VERSION ""

NS_ :

BS_:

BU_: PPowerSource
VAL_TABLE_ MeasurementsTable 5 "Description for the value '0x5'" 4 "Description for the value '0x4'" 3 "Description for the value '0x3'" 2 "Description for the value '0x2'" 1 "Description for the value '0x1'" 0 "Description for the value '0x0'" ;

BO_ 3221225472 VECTOR__INDEPENDENT_SIG_MSG: 0 Vector__XXX
 SG_ Get_Prot_RMS_Current_Level : 0|32@1- (1,0) [0|10] "" Vector__XXX
 SG_ Get_A_Apparent_Power : 0|32@1- (1,0) [-3.4E+038|3.4E+038] "" Vector__XXX
 SG_ Get_A_Current_AC : 0|32@1- (1,0) [-3.4E+038|3.4E+038] "A" Vector__XXX
 SG_ Get_VoltageLL_ACDC : 0|32@1- (1,0) [-3.4E+038|3.4E+038] "V" Vector__XXX
 SG_ Get_VoltageLL_AC : 0|32@1- (1,0) [-3.4E+038|3.4E+038] "V" Vector__XXX
 SG_ Get_VoltageLL_DC : 0|32@1- (1,0) [-3.4E+038|3.4E+038] "V" Vector__XXX
 SG_ Get_Voltage_ACDC : 0|32@1- (1,0) [-3.4E+038|3.4E+038] "V" Vector__XXX
 SG_ Get_Current_ACDC : 0|32@1- (1,0) [-3.4E+038|3.4E+038] "A" Vector__XXX
 SG_ Get_Current_AC : 0|32@1- (1,0) [-3.4E+038|3.4E+038] "A" Vector__XXX
 SG_ Get_Current_DC : 0|32@1- (1,0) [-3.4E+038|3.4E+038] "A" Vector__XXX
 SG_ Get_Peak_Current : 0|32@1- (1,0) [-3.4E+038|3.4E+038] "A" Vector__XXX
 SG_ Get_Peak_Current_Recorded : 0|32@1- (1,0) [-3.4E+038|3.4E+038] "" Vector__XXX
 SG_ Get_Active_Power : 0|32@1- (1,0) [-3.4E+038|3.4E+038] "" Vector__XXX
 SG_ Get_Apparent_Power : 0|32@1- (1,0) [-3.4E+038|3.4E+038] "" Vector__XXX
 SG_ Get_Power_Factor : 0|32@1- (1,0) [-3.4E+038|3.4E+038] "" Vector__XXX
 SG_ Get_Crest_Factor : 0|32@1- (1,0) [-3.4E+038|3.4E+038] "" Vector__XXX
 SG_ Get_Voltage_THD : 0|32@1- (1,0) [-3.4E+038|3.4E+038] "" Vector__XXX
 SG_ Get_Current_THD : 0|32@1- (1,0) [-3.4E+038|3.4E+038] "" Vector__XXX
 SG_ Get_Power_Factor_Angle : 0|32@1- (1,0) [-3.4E+038|3.4E+038] "" Vector__XXX
 SG_ Get_Displacement_Factor : 0|32@1- (1,0) [-3.4E+038|3.4E+038] "" Vector__XXX
 SG_ Get_Distortion_Factor : 0|32@1- (1,0) [-3.4E+038|3.4E+038] "" Vector__XXX
 SG_ Get_Kilowatt_Hour : 0|32@1- (1,0) [-3.4E+038|3.4E+038] "kWh" Vector__XXX
 SG_ Get_KWH_Elapsed_Time : 0|32@1- (1,0) [-3.4E+038|3.4E+038] "" Vector__XXX
 SG_ Get_C_VoltageLL_ACDC : 0|32@1- (1,0) [-3.4E+038|3.4E+038] "V" Vector__XXX
 SG_ Get_C_VoltageLL_AC : 0|32@1- (1,0) [-3.4E+038|3.4E+038] "V" Vector__XXX
 SG_ Get_C_VoltageLL_DC : 0|32@1- (1,0) [-3.4E+038|3.4E+038] "V" Vector__XXX
 SG_ Get_C_Voltage_ACDC : 0|32@1- (1,0) [-3.4E+038|3.4E+038] "V" Vector__XXX
 SG_ Get_C_Voltage_DC : 0|32@1- (1,0) [-3.4E+038|3.4E+038] "V" Vector__XXX
 SG_ Get_C_Peak_Current_Recorded : 0|32@1- (1,0) [-3.4E+038|3.4E+038] "" Vector__XXX
 SG_ Get_C_Active_Power : 0|32@1- (1,0) [-3.4E+038|3.4E+038] "" Vector__XXX
 SG_ Get_C_Apparent_Power : 0|32@1- (1,0) [-3.4E+038|3.4E+038] "" Vector__XXX
 SG_ Get_C_Crest_Factor : 0|32@1- (1,0) [-3.4E+038|3.4E+038] "" Vector__XXX
 SG_ Get_C_Voltage_THD : 0|32@1- (1,0) [-3.4E+038|3.4E+038] "" Vector__XXX
 SG_ Get_C_Power_Factor_Angle : 0|32@1- (1,0) [-3.4E+038|3.4E+038] "" Vector__XXX
 SG_ Get_C_Distortion_Factor : 0|32@1- (1,0) [-3.4E+038|3.4E+038] "" Vector__XXX
 SG_ Get_C_Kilowatt_Hour : 0|32@1- (1,0) [-3.4E+038|3.4E+038] "kWh" Vector__XXX
 SG_ Get_C_KWH_Elapsed_Time : 0|32@1- (1,0) [-3.4E+038|3.4E+038] "" Vector__XXX
 SG_ Get_B_Frequency : 0|32@1- (1,0) [-3.4E+038|3.4E+038] "Hz" Vector__XXX
 SG_ Get_B_VoltageLL_ACDC : 0|32@1- (1,0) [-3.4E+038|3.4E+038] "V" Vector__XXX
 SG_ Get_B_VoltageLL_AC : 0|32@1- (1,0) [-3.4E+038|3.4E+038] "V" Vector__XXX
 SG_ Get_B_VoltageLL_DC : 0|32@1- (1,0) [-3.4E+038|3.4E+038] "V" Vector__XXX
 SG_ Get_B_Voltage_ACDC : 0|32@1- (1,0) [-3.4E+038|3.4E+038] "V" Vector__XXX
 SG_ Get_B_Voltage_DC : 0|32@1- (1,0) [-3.4E+038|3.4E+038] "V" Vector__XXX
 SG_ Get_B_Current_ACDC : 0|32@1- (1,0) [-3.4E+038|3.4E+038] "A" Vector__XXX
 SG_ Get_B_Current_AC : 0|32@1- (1,0) [-3.4E+038|3.4E+038] "A" Vector__XXX
 SG_ Get_B_Current_DC : 0|32@1- (1,0) [-3.4E+038|3.4E+038] "A" Vector__XXX
 SG_ Get_B_Peak_Current : 0|32@1- (1,0) [-3.4E+038|3.4E+038] "A" Vector__XXX
 SG_ Get_B_Peak_Current_Recorded : 0|32@1- (1,0) [-3.4E+038|3.4E+038] "" Vector__XXX
 SG_ Get_B_Active_Power : 0|32@1- (1,0) [-3.4E+038|3.4E+038] "" Vector__XXX
 SG_ Get_B_Apparent_Power : 0|32@1- (1,0) [-3.4E+038|3.4E+038] "" Vector__XXX
 SG_ Get_B_Power_Factor : 0|32@1- (1,0) [-3.4E+038|3.4E+038] "" Vector__XXX
 SG_ Get_B_Crest_Factor : 0|32@1- (1,0) [-3.4E+038|3.4E+038] "" Vector__XXX
 SG_ Get_B_Voltage_THD : 0|32@1- (1,0) [-3.4E+038|3.4E+038] "" Vector__XXX
 SG_ Get_B_Current_THD : 0|32@1- (1,0) [-3.4E+038|3.4E+038] "" Vector__XXX
 SG_ Get_B_Power_Factor_Angle : 0|32@1- (1,0) [-3.4E+038|3.4E+038] "" Vector__XXX
 SG_ Get_B_Displacement_Factor : 0|32@1- (1,0) [-3.4E+038|3.4E+038] "" Vector__XXX
 SG_ Get_B_Distortion_Factor : 0|32@1- (1,0) [-3.4E+038|3.4E+038] "" Vector__XXX
 SG_ Get_B_Kilowatt_Hour : 0|32@1- (1,0) [-3.4E+038|3.4E+038] "kWh" Vector__XXX
 SG_ Get_B_KWH_Elapsed_Time : 0|32@1- (1,0) [-3.4E+038|3.4E+038] "" Vector__XXX
 SG_ Get_A_VoltageLL_DC : 0|32@1- (1,0) [-3.4E+038|3.4E+038] "V" Vector__XXX
 SG_ Get_A_VoltageLL_ACDC : 0|32@1- (1,0) [-3.4E+038|3.4E+038] "V" Vector__XXX
 SG_ Get_A_VoltageLL_AC : 0|32@1- (1,0) [-3.4E+038|3.4E+038] "V" Vector__XXX
 SG_ Get_A_Voltage_THD : 0|32@1- (1,0) [-3.4E+038|3.4E+038] "" Vector__XXX
 SG_ Get_A_Voltage_ACDC : 0|32@1- (1,0) [-3.4E+038|3.4E+038] "V" Vector__XXX
 SG_ Get_A_Power_Factor_Angle : 0|32@1- (1,0) [-3.4E+038|3.4E+038] "" Vector__XXX
 SG_ Get_A_Power_Factor : 0|32@1- (1,0) [-3.4E+038|3.4E+038] "" Vector__XXX
 SG_ Get_A_Peak_Current_Recorded : 0|32@1- (1,0) [-3.4E+038|3.4E+038] "" Vector__XXX
 SG_ Get_A_Peak_Current : 0|32@1- (1,0) [-3.4E+038|3.4E+038] "A" Vector__XXX
 SG_ Get_A_KWH_Elapsed_Time : 0|32@1- (1,0) [-3.4E+038|3.4E+038] "" Vector__XXX
 SG_ Get_A_Kilowatt_Hour : 0|32@1- (1,0) [-3.4E+038|3.4E+038] "kWh" Vector__XXX
 SG_ Get_A_Frequency : 0|32@1- (1,0) [-3.4E+038|3.4E+038] "Hz" Vector__XXX
 SG_ Get_A_Distortion_Factor : 0|32@1- (1,0) [-3.4E+038|3.4E+038] "" Vector__XXX
 SG_ Get_A_Displacement_Factor : 0|32@1- (1,0) [-3.4E+038|3.4E+038] "" Vector__XXX
 SG_ Get_A_Current_THD : 0|32@1- (1,0) [-3.4E+038|3.4E+038] "" Vector__XXX
 SG_ Get_A_Current_DC : 0|32@1- (1,0) [-3.4E+038|3.4E+038] "A" Vector__XXX
 SG_ Get_A_Current_ACDC : 0|32@1- (1,0) [-3.4E+038|3.4E+038] "A" Vector__XXX
 SG_ Get_A_Crest_Factor : 0|32@1- (1,0) [-3.4E+038|3.4E+038] "" Vector__XXX
 SG_ Get_A_Active_Power : 0|32@1- (1,0) [-3.4E+038|3.4E+038] "" Vector__XXX
 SG_ Firmware_Version : 0|16@1+ (1,0) [0|65535] "" Vector__XXX
 SG_ Can_Version : 0|16@1+ (1,0) [0|65535] "" Vector__XXX
 SG_ SCPI_Response_Next_Page : 0|8@1+ (1,0) [0|10] "" Vector__XXX
 SG_ SCPI_Char_16_Endianess : 0|8@1+ (1,0) [0|10] "" Vector__XXX
 SG_ SCPI_COMMAND_LAST_ASWER : 0|16@1+ (1,0) [0|255] "" Vector__XXX
 SG_ SCPI_WRITE_QUERY : 0|16@1+ (1,0) [0|255] "" Vector__XXX
 SG_ Protection_Peak_Voltage_Level : 0|32@1- (1,0) [-3.4E+038|3.4E+038] "" Vector__XXX
 SG_ Protection_Peak_Voltage_Margin : 0|32@1- (1,0) [-3.4E+038|3.4E+038] "" Vector__XXX
 SG_ Protection_Peak_Current_Level : 0|32@1- (1,0) [-3.4E+038|3.4E+038] "" Vector__XXX
 SG_ Protection_Peak_Current_Limit : 0|32@1- (1,0) [-3.4E+038|3.4E+038] "" Vector__XXX
 SG_ Protection_Trip_Time : 0|32@1- (1,0) [-3.4E+038|3.4E+038] "" Vector__XXX
 SG_ Protection_RMS_Current_Level : 0|32@1- (1,0) [-3.4E+038|3.4E+038] "" Vector__XXX
 SG_ Set_Enable_KWH : 0|8@1+ (1,0) [0|10] "" Vector__XXX
 SG_ Set_Reset_KWH : 0|8@1+ (1,0) [0|10] "" Vector__XXX
 SG_ Periodic_C_KWH_Elapsed_Time : 0|32@1- (1,0) [-3.4E+038|3.4E+038] "" Vector__XXX
 SG_ Periodic_B_KWH_Elapsed_Time : 0|32@1- (1,0) [-3.4E+038|3.4E+038] "" Vector__XXX
 SG_ Periodic_A_KWH_Elapsed_Time : 0|32@1- (1,0) [-3.4E+038|3.4E+038] "" Vector__XXX
 SG_ Periodic_C_Kilowatt_Hour : 0|32@1- (1,0) [-3.4E+038|3.4E+038] "kWh" Vector__XXX
 SG_ Periodic_B_Kilowatt_Hour : 0|32@1- (1,0) [-3.4E+038|3.4E+038] "kWh" Vector__XXX
 SG_ Periodic_C_Distortion_Factor : 0|32@1- (1,0) [-3.4E+038|3.4E+038] "" Vector__XXX
 SG_ Periodic_B_Distortion_Factor : 0|32@1- (1,0) [-3.4E+038|3.4E+038] "" Vector__XXX
 SG_ Periodic_A_Distortion_Factor : 0|32@1- (1,0) [-3.4E+038|3.4E+038] "" Vector__XXX
 SG_ Periodic_C_Displacement_Factor : 0|32@1- (1,0) [-3.4E+038|3.4E+038] "" Vector__XXX
 SG_ Periodic_B_Displacement_Factor : 0|32@1- (1,0) [-3.4E+038|3.4E+038] "" Vector__XXX
 SG_ Periodic_A_Displacement_Factor : 0|32@1- (1,0) [-3.4E+038|3.4E+038] "" Vector__XXX
 SG_ Periodic_C_Power_Factor_Angle : 0|32@1- (1,0) [-3.4E+038|3.4E+038] "" Vector__XXX
 SG_ Periodic_B_Power_Factor_Angle : 0|32@1- (1,0) [-3.4E+038|3.4E+038] "" Vector__XXX
 SG_ Periodic_C_Current_THD : 0|32@1- (1,0) [-3.4E+038|3.4E+038] "" Vector__XXX
 SG_ Periodic_B_Current_THD : 0|32@1- (1,0) [-3.4E+038|3.4E+038] "" Vector__XXX
 SG_ Periodic_C_Voltage_THD : 0|32@1- (1,0) [-3.4E+038|3.4E+038] "" Vector__XXX
 SG_ Periodic_B_Voltage_THD : 0|32@1- (1,0) [-3.4E+038|3.4E+038] "" Vector__XXX
 SG_ Periodic_C_Peak_Current_Recoded : 0|32@1- (1,0) [-3.4E+038|3.4E+038] "" Vector__XXX
 SG_ Periodic_B_Peak_Current_Recoded : 0|32@1- (1,0) [-3.4E+038|3.4E+038] "" Vector__XXX
 SG_ Periodic_C_Crest_Factor : 0|32@1- (1,0) [-3.4E+038|3.4E+038] "" Vector__XXX
 SG_ Periodic_B_Crest_Factor : 0|32@1- (1,0) [-3.4E+038|3.4E+038] "" Vector__XXX
 SG_ Periodic_A_Crest_Factor : 0|32@1- (1,0) [-3.4E+038|3.4E+038] "" Vector__XXX
 SG_ Periodic_C_Power_Factor : 0|32@1- (1,0) [-3.4E+038|3.4E+038] "" Vector__XXX
 SG_ Periodic_B_Power_Factor : 0|32@1- (1,0) [-3.4E+038|3.4E+038] "" Vector__XXX
 SG_ Periodic_C_Peak_Current : 0|32@1- (1,0) [-3.4E+038|3.4E+038] "A" Vector__XXX
 SG_ Periodic_B_Peak_Current : 0|32@1- (1,0) [-3.4E+038|3.4E+038] "A" Vector__XXX
 SG_ Periodic_C_Active_Power : 0|32@1- (1,0) [-3.4E+038|3.4E+038] "" Vector__XXX
 SG_ Periodic_C_Current_DC : 0|32@1- (1,0) [-3.4E+038|3.4E+038] "A" Vector__XXX
 SG_ Periodic_B_Current_DC : 0|32@1- (1,0) [-3.4E+038|3.4E+038] "A" Vector__XXX
 SG_ Periodic_C_Current_ACDC : 0|32@1- (1,0) [-3.4E+038|3.4E+038] "A" Vector__XXX
 SG_ Periodic_B_Current_ACDC : 0|32@1- (1,0) [-3.4E+038|3.4E+038] "A" Vector__XXX
 SG_ Periodic_C_Voltage_DC : 0|32@1- (1,0) [-3.4E+038|3.4E+038] "V" Vector__XXX
 SG_ Periodic_B_Voltage_DC : 0|32@1- (1,0) [-3.4E+038|3.4E+038] "V" Vector__XXX
 SG_ Periodic_C_Voltage_AC : 0|32@1- (1,0) [-3.4E+038|3.4E+038] "V" Vector__XXX
 SG_ Periodic_B_Voltage_AC : 0|32@1- (1,0) [-3.4E+038|3.4E+038] "V" Vector__XXX
 SG_ Periodic_C_Voltage_ACDC : 0|32@1- (1,0) [-3.4E+038|3.4E+038] "V" Vector__XXX
 SG_ Periodic_B_Voltage_ACDC : 0|32@1- (1,0) [-3.4E+038|3.4E+038] "V" Vector__XXX
 SG_ Periodic_C_VoltageLL_DC : 0|32@1- (1,0) [-3.4E+038|3.4E+038] "V" Vector__XXX
 SG_ Periodic_B_VoltageLL_DC : 0|32@1- (1,0) [-3.4E+038|3.4E+038] "V" Vector__XXX
 SG_ Periodic_C_VoltageLL_AC : 0|32@1- (1,0) [-3.4E+038|3.4E+038] "V" Vector__XXX
 SG_ Periodic_B_VoltageLL_AC : 0|32@1- (1,0) [-3.4E+038|3.4E+038] "V" Vector__XXX
 SG_ Periodic_C_VoltageLL_ACDC : 0|32@1- (1,0) [-3.4E+038|3.4E+038] "V" Vector__XXX
 SG_ Periodic_B_VoltageLL_ACDC : 0|32@1- (1,0) [-3.4E+038|3.4E+038] "V" Vector__XXX
 SG_ Periodic_C_Frequency : 0|32@1- (1,0) [-3.4E+038|3.4E+038] "Hz" Vector__XXX
 SG_ Periodic_B_Frequency : 0|32@1- (1,0) [-3.4E+038|3.4E+038] "Hz" Vector__XXX
 SG_ Periodic_A_Frequency : 0|32@1- (1,0) [-3.4E+038|3.4E+038] "Hz" Vector__XXX
 SG_ Get_Set_Phase_Offset_Output_C : 0|32@1- (1,0) [-3.4E+038|3.4E+038] "" Vector__XXX
 SG_ Get_Set_Phase_Offset_Output_B : 0|32@1- (1,0) [-3.4E+038|3.4E+038] "" Vector__XXX
 SG_ Get_Set_KVA_Limit_C : 0|32@1- (1,0) [-3.4E+038|3.4E+038] "" Vector__XXX
 SG_ Get_Set_KVA_Limit_B : 0|32@1- (1,0) [-3.4E+038|3.4E+038] "" Vector__XXX
 SG_ Get_Set_KVA_Limit_A : 0|32@1- (1,0) [-3.4E+038|3.4E+038] "" Vector__XXX
 SG_ Get_Set_Current_Limit_C : 0|32@1- (1,0) [-3.4E+038|3.4E+038] "" Vector__XXX
 SG_ Get_Set_Current_Limit_B : 0|32@1- (1,0) [-3.4E+038|3.4E+038] "" Vector__XXX
 SG_ Get_Set_Power_Limit_C : 0|32@1- (1,0) [-3.4E+038|3.4E+038] "" Vector__XXX
 SG_ Get_Set_Power_Limit_B : 0|32@1- (1,0) [-3.4E+038|3.4E+038] "" Vector__XXX
 SG_ Get_Set_Power_Limit_A : 0|32@1- (1,0) [-3.4E+038|3.4E+038] "" Vector__XXX
 SG_ Get_Set_Program_Voltage_DC_C : 0|32@1- (1,0) [-3.4E+038|3.4E+038] "" Vector__XXX
 SG_ Get_Set_Program_Voltage_DC_B : 0|32@1- (1,0) [-3.4E+038|3.4E+038] "" Vector__XXX
 SG_ Get_Set_Program_Voltage_DC_A : 0|32@1- (1,0) [-3.4E+038|3.4E+038] "" Vector__XXX
 SG_ Get_Set_Program_Voltage_AC_C : 0|32@1- (1,0) [-3.4E+038|3.4E+038] "" Vector__XXX
 SG_ Get_Set_Program_Voltage_AC_B : 0|32@1- (1,0) [-3.4E+038|3.4E+038] "" Vector__XXX
 SG_ Get_Set_Program_Voltage_AC_A : 0|32@1- (1,0) [-3.4E+038|3.4E+038] "" Vector__XXX
 SG_ Get_Set_Program_Voltage_AC : 0|32@1- (1,0) [-3.4E+038|3.4E+038] "" Vector__XXX
 SG_ Get_Set_Program_Frequency_C : 0|32@1- (1,0) [-3.4E+038|3.4E+038] "" Vector__XXX
 SG_ Get_Set_Program_Frequency_B : 0|32@1- (1,0) [-3.4E+038|3.4E+038] "" Vector__XXX
 SG_ Get_Set_Program_Frequency_A : 0|32@1- (1,0) [-3.4E+038|3.4E+038] "" Vector__XXX
 SG_ Get_Prot_Peak_Voltage_Level : 0|32@1- (1,0) [-3.4E+038|3.4E+038] "" Vector__XXX
 SG_ Get_Prot_Peak_Voltage_Margin : 0|32@1- (1,0) [-3.4E+038|3.4E+038] "" Vector__XXX
 SG_ Get_Prot_Peak_Current_Level : 0|32@1- (1,0) [-3.4E+038|3.4E+038] "" Vector__XXX
 SG_ Get_Prot_Peak_Current_Limit : 0|32@1- (1,0) [-3.4E+038|3.4E+038] "" Vector__XXX
 SG_ Get_Prot_Trip_Time : 0|32@1- (1,0) [-3.4E+038|3.4E+038] "" Vector__XXX
 SG_ Protection_Power_Level : 0|32@1- (1,0) [-3.4E+038|3.4E+038] "" Vector__XXX
 SG_ Protection_KVA_Level : 0|32@1- (1,0) [-3.4E+038|3.4E+038] "" Vector__XXX
 SG_ Protection_RMS_Power : 0|8@1+ (1,0) [0|10] "" Vector__XXX
 SG_ Protection_RMS_Current : 0|8@1+ (1,0) [0|10] "" Vector__XXX
 SG_ Protection_Peak_Voltage_Mode : 0|8@1+ (1,0) [0|10] "" Vector__XXX
 SG_ Protection_Peak_Voltage : 0|8@1+ (1,0) [0|10] "" Vector__XXX
 SG_ Protection_Peak_Current : 0|8@1+ (1,0) [0|10] "" Vector__XXX
 SG_ Get_Prot_KVA_Level : 0|32@1- (1,0) [-3.4E+038|3.4E+038] "" Vector__XXX
 SG_ Get_Prot_Power_Level : 0|32@1- (1,0) [-3.4E+038|3.4E+038] "" Vector__XXX
 SG_ Get_Prot_RMS_Power : 0|8@1+ (1,0) [0|10] "" Vector__XXX
 SG_ Get_Prot_RMS_Current : 0|8@1+ (1,0) [0|10] "" Vector__XXX
 SG_ Get_Prot_Peak_Voltage_Mode : 0|8@1+ (1,0) [0|10] "" Vector__XXX
 SG_ Get_Prot_Peak_Current : 0|8@1+ (1,0) [0|10] "" Vector__XXX
 SG_ Get_Prot_Peak_Voltage : 0|8@1+ (1,0) [0|10] "" Vector__XXX
 SG_ Get_Set_Enable_Output : 0|8@1+ (1,0) [0|255] "" Vector__XXX
 SG_ Get_Set_Program_Voltage_DC : 0|32@1- (1,0) [-3.4E+038|3.4E+038] "" Vector__XXX
 SG_ Get_Set_Power_Limit : 0|32@1- (1,0) [-3.4E+038|3.4E+038] "" Vector__XXX
 SG_ Get_Set_KVA_Limit : 0|32@1- (1,0) [-3.4E+038|3.4E+038] "" Vector__XXX
 SG_ Get_Set_Current_Limit : 0|32@1- (1,0) [-3.4E+038|3.4E+038] "" Vector__XXX
 SG_ Get_Set_Current_Limit_A : 0|32@1- (1,0) [-3.4E+038|3.4E+038] "" Vector__XXX
 SG_ Multiplex_Get_Setpoints : 0|8@1+ (1,0) [0|0] "" Vector__XXX
 SG_ Get_Set_Program_Frequency : 0|32@1- (1,0) [-3.4E+038|3.4E+038] "" Vector__XXX
 SG_ Get_B_Voltage_AC : 0|32@1- (1,0) [-3.4E+038|3.4E+038] "V" Vector__XXX
 SG_ Get_Frequency : 0|32@1- (1,0) [-3.4E+038|3.4E+038] "Hz" Vector__XXX
 SG_ Multiplex_Get_Values : 0|8@1+ (1,0) [0|0] "" Vector__XXX
 SG_ Get_C_Power_Factor : 0|32@1- (1,0) [-3.4E+038|3.4E+038] "" Vector__XXX
 SG_ Get_C_Peak_Current : 0|32@1- (1,0) [-3.4E+038|3.4E+038] "A" Vector__XXX
 SG_ Get_C_Frequency : 0|32@1- (1,0) [-3.4E+038|3.4E+038] "Hz" Vector__XXX
 SG_ Get_C_Displacement_Factor : 0|32@1- (1,0) [-3.4E+038|3.4E+038] "" Vector__XXX
 SG_ Get_C_Current_THD : 0|32@1- (1,0) [-3.4E+038|3.4E+038] "" Vector__XXX
 SG_ Get_C_Current_DC : 0|32@1- (1,0) [-3.4E+038|3.4E+038] "A" Vector__XXX
 SG_ Get_C_Current_ACDC : 0|32@1- (1,0) [-3.4E+038|3.4E+038] "A" Vector__XXX
 SG_ Get_C_Current_AC : 0|32@1- (1,0) [-3.4E+038|3.4E+038] "A" Vector__XXX
 SG_ Get_C_Voltage_AC : 0|32@1- (1,0) [-3.4E+038|3.4E+038] "V" Vector__XXX
 SG_ Get_A_Voltage_DC : 0|32@1- (1,0) [-3.4E+038|3.4E+038] "V" Vector__XXX
 SG_ Get_A_Voltage_AC : 0|32@1- (1,0) [-3.4E+038|3.4E+038] "V" Vector__XXX
 SG_ Multiplex_Periodic_Values_2 : 0|8@1+ (1,0) [0|0] "" Vector__XXX
 SG_ Periodic_A_Current_THD : 0|32@1- (1,0) [-3.4E+038|3.4E+038] "" Vector__XXX
 SG_ Periodic_A_Current_DC : 0|32@1- (1,0) [-3.4E+038|3.4E+038] "A" Vector__XXX
 SG_ Periodic_A_Current_ACDC : 0|32@1- (1,0) [-3.4E+038|3.4E+038] "A" Vector__XXX
 SG_ Multiplex_Periodic_Values_1 : 0|8@1+ (1,0) [0|0] "" Vector__XXX
 SG_ Ack_App_Signal : 0|16@1+ (1,0) [0|15] "" Vector__XXX
 SG_ Setpoint_Power_Limit_C : 0|32@1- (1,0) [-3.4E+038|3.4E+038] "" Vector__XXX
 SG_ Setpoint_Power_Limit_B : 0|32@1- (1,0) [-3.4E+038|3.4E+038] "" Vector__XXX
 SG_ Setpoint_Power_Limit_A : 0|32@1- (1,0) [-3.4E+038|3.4E+038] "" Vector__XXX
 SG_ Setpoint_Power_Limit : 0|32@1- (1,0) [-3.4E+038|3.4E+038] "" Vector__XXX
 SG_ Setpoint_Phase_Offset_Output_C : 0|32@1- (1,0) [-3.4E+038|3.4E+038] "" Vector__XXX
 SG_ Setpoint_Phase_Offset_Output_B : 0|32@1- (1,0) [-3.4E+038|3.4E+038] "" Vector__XXX
 SG_ Setpoint_KVA_Limit_C : 0|32@1- (1,0) [-3.4E+038|3.4E+038] "" Vector__XXX
 SG_ Setpoint_KVA_Limit_B : 0|32@1- (1,0) [-3.4E+038|3.4E+038] "" Vector__XXX
 SG_ Setpoint_KVA_Limit_A : 0|32@1- (1,0) [-3.4E+038|3.4E+038] "" Vector__XXX
 SG_ Setpoint_KVA_Limit : 0|32@1- (1,0) [-3.4E+038|3.4E+038] "" Vector__XXX
 SG_ Setpoint_Enable_Output : 0|8@1+ (1,0) [0|10] "" Vector__XXX
 SG_ Setpoint_Current_Limit_C : 0|32@1- (1,0) [-3.4E+038|3.4E+038] "" Vector__XXX
 SG_ Setpoint_Current_Limit_B : 0|32@1- (1,0) [-3.4E+038|3.4E+038] "" Vector__XXX
 SG_ Setpoint_Current_Limit : 0|32@1- (1,0) [-3.4E+038|3.4E+038] "" Vector__XXX
 SG_ Setpoint_Current_Limit_A : 0|32@1- (1,0) [-3.4E+038|3.4E+038] "" Vector__XXX
 SG_ Setpoint_Program_Voltage_DC_C : 0|32@1- (1,0) [-3.4E+038|3.4E+038] "" Vector__XXX
 SG_ Setpoint_Program_Voltage_DC_B : 0|32@1- (1,0) [-3.4E+038|3.4E+038] "" Vector__XXX
 SG_ Setpoint_Program_Voltage_DC_A : 0|32@1- (1,0) [-3.4E+038|3.4E+038] "" Vector__XXX
 SG_ Setpoint_Program_Voltage_DC : 0|32@1- (1,0) [-3.4E+038|3.4E+038] "" Vector__XXX
 SG_ Setpoint_Program_Voltage_AC_C : 0|32@1- (1,0) [-3.4E+038|3.4E+038] "" Vector__XXX
 SG_ Setpoint_Program_Voltage_AC_B : 0|32@1- (1,0) [-3.4E+038|3.4E+038] "" Vector__XXX
 SG_ Setpoint_Program_Voltage_AC_A : 0|32@1- (1,0) [-3.4E+038|3.4E+038] "" Vector__XXX
 SG_ Setpoint_Program_Voltage_AC : 0|32@1- (1,0) [-3.4E+038|3.4E+038] "" Vector__XXX
 SG_ Setpoint_Program_Frequency_C : 0|32@1- (1,0) [-3.4E+038|3.4E+038] "" Vector__XXX
 SG_ Setpoint_Program_Frequency_B : 0|32@1- (1,0) [-3.4E+038|3.4E+038] "" Vector__XXX
 SG_ Setpoint_Program_Frequency_A : 0|32@1- (1,0) [-3.4E+038|3.4E+038] "" Vector__XXX
 SG_ Setpoint_Program_Frequency : 0|32@1- (1,0) [-3.4E+038|3.4E+038] "" Vector__XXX
 SG_ Multiplex_Setpoint_Program : 0|8@1+ (1,0) [0|255] "" Vector__XXX
 SG_ Get_Con_Slew_Voltage_DC : 0|32@1- (1,0) [-3.4E+038|3.4E+038] "" Vector__XXX
 SG_ Get_Con_Slew_Voltage_AC : 0|32@1- (1,0) [-3.4E+038|3.4E+038] "" Vector__XXX
 SG_ Get_Con_Slew_Ramp_Time : 0|32@1- (1,0) [-3.4E+038|3.4E+038] "s" Vector__XXX
 SG_ Get_Con_Slew_Phase : 0|32@1- (1,0) [-3.4E+038|3.4E+038] "" Vector__XXX
 SG_ Get_Con_Slew_Frequency : 0|32@1- (1,0) [-3.4E+038|3.4E+038] "" Vector__XXX
 SG_ Config_Slew_Voltage_DC : 0|32@1- (1,0) [-3.4E+038|3.4E+038] "" Vector__XXX
 SG_ Config_Slew_Voltage_AC : 0|32@1- (1,0) [-3.4E+038|3.4E+038] "" Vector__XXX
 SG_ Config_Slew_Ramp_Time : 0|32@1- (1,0) [-3.4E+038|3.4E+038] "s" Vector__XXX
 SG_ Config_Slew_Phase : 0|32@1- (1,0) [-3.4E+038|3.4E+038] "" Vector__XXX
 SG_ Multiplex_Config_Slew : 0|4@1+ (1,0) [0|15] "" Vector__XXX
 SG_ Config_Slew_Frequency : 0|32@1- (1,0) [-3.4E+038|3.4E+038] "" Vector__XXX
 SG_ Get_Con_Unit_Max_CSC_Gain : 0|32@1- (1,0) [-3.4E+038|3.4E+038] "" Vector__XXX
 SG_ Get_Con_Unit_Out_Phase_Disable : 0|32@1- (1,0) [-3.4E+038|3.4E+038] "" Vector__XXX
 SG_ Get_Con_Unit_Update_Phase : 0|32@1- (1,0) [-3.4E+038|3.4E+038] "" Vector__XXX
 SG_ Config_Unit_Update_Phase : 0|32@1- (1,0) [-3.4E+038|3.4E+038] "" Vector__XXX
 SG_ Config_Unit_Out_Phase_Disable : 0|32@1- (1,0) [-3.4E+038|3.4E+038] "" Vector__XXX
 SG_ Config_Unit_Max_CSC_Gain : 0|32@1- (1,0) [-3.4E+038|3.4E+038] "" Vector__XXX
 SG_ Multiplexor_Config_Unit : 0|8@1+ (1,0) [0|15] "" Vector__XXX
 SG_ Config_Unit_Voltage_Range : 0|8@1+ (1,0) [0|255] "" Vector__XXX
 SG_ Config_Unit_Phase_Rotation : 0|8@1+ (1,0) [0|255] "" Vector__XXX
 SG_ Config_Unit_Out_Impedance_Mode : 0|8@1+ (1,0) [0|255] "" Vector__XXX
 SG_ Config_Unit_Mode : 0|8@1+ (1,0) [0|255] "" Vector__XXX
 SG_ Config_Unit_Form : 0|8@1+ (1,0) [1|255] "" Vector__XXX
 SG_ Config_Unit_Fault_On_Saturation : 0|8@1+ (1,0) [0|255] "" Vector__XXX
 SG_ Config_Unit_C_Self_Calibration : 0|8@1+ (1,0) [0|255] "" Vector__XXX

BO_ 119 Recep_meas: 8 Vector__XXX
 SG_ Get_Voltage_DC : 32|32@1- (1,0) [-3.4E+038|3.4E+038] "V" Vector__XXX
 SG_ Get_Voltage_AC : 0|32@1- (1,0) [-3.4E+038|3.4E+038] "V" Vector__XXX

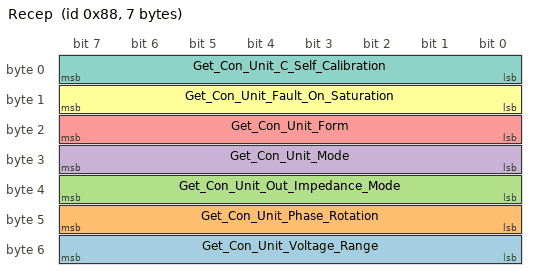
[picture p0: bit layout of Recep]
BO_ 136 Recep: 7 Vector__XXX
 SG_ Get_Con_Unit_Voltage_Range : 48|8@1+ (1,0) [0|255] "" Vector__XXX
 SG_ Get_Con_Unit_Phase_Rotation : 40|8@1+ (1,0) [0|10] "" Vector__XXX
 SG_ Get_Con_Unit_Out_Impedance_Mode : 32|8@1+ (1,0) [0|255] "" Vector__XXX
 SG_ Get_Con_Unit_Mode : 24|8@1+ (1,0) [0|255] "" Vector__XXX
 SG_ Get_Con_Unit_Form : 16|8@1+ (1,0) [1|255] "" Vector__XXX
 SG_ Get_Con_Unit_Fault_On_Saturation : 8|8@1+ (1,0) [0|255] "" Vector__XXX
 SG_ Get_Con_Unit_C_Self_Calibration : 0|8@1+ (1,0) [0|255] "" Vector__XXX

BO_ 3 Periodic_Measurements_Total: 6 Vector__XXX
 SG_ Multiplex_Periodic_Values_2 M : 0|8@1+ (1,0) [0|0] "" Vector__XXX
 SG_ Periodic_VoltageLL_DC m23 : 8|32@1- (1,0) [-3.4E+038|3.4E+038] "V" Vector__XXX
 SG_ Periodic_VoltageLL_ACDC m22 : 8|32@1- (1,0) [-3.4E+038|3.4E+038] "V" Vector__XXX
 SG_ Periodic_VoltageLL_AC m21 : 8|32@1- (1,0) [-3.4E+038|3.4E+038] "V" Vector__XXX
 SG_ Periodic_Voltage_THD m19 : 8|32@1- (1,0) [-3.4E+038|3.4E+038] "" Vector__XXX
 SG_ Periodic_Voltage_DC m18 : 8|32@1- (1,0) [-3.4E+038|3.4E+038] "V" Vector__XXX
 SG_ Periodic_Voltage_ACDC m17 : 8|32@1- (1,0) [-3.4E+038|3.4E+038] "V" Vector__XXX
 SG_ Periodic_Voltage_AC m16 : 8|32@1- (1,0) [-3.4E+038|3.4E+038] "V" Vector__XXX
 SG_ Periodic_Power_Factor_Angle m15 : 8|32@1- (1,0) [-3.4E+038|3.4E+038] "" Vector__XXX
 SG_ Periodic_Power_Factor m14 : 8|32@1- (1,0) [-3.4E+038|3.4E+038] "" Vector__XXX
 SG_ Periodic_Peak_Current_Recoded m13 : 8|32@1- (1,0) [-3.4E+038|3.4E+038] "" Vector__XXX
 SG_ Periodic_Peak_Current m12 : 8|32@1- (1,0) [-3.4E+038|3.4E+038] "A" Vector__XXX
 SG_ Periodic_KWH_Elapsed_Time m11 : 8|32@1- (1,0) [-3.4E+038|3.4E+038] "" Vector__XXX
 SG_ Periodic_Kilowatt_Hour m10 : 8|32@1- (1,0) [-3.4E+038|3.4E+038] "kWh" Vector__XXX
 SG_ Periodic_Frequency m9 : 8|32@1- (1,0) [-3.4E+038|3.4E+038] "Hz" Vector__XXX
 SG_ Periodic_Distortion_Factor m8 : 8|32@1- (1,0) [-3.4E+038|3.4E+038] "" Vector__XXX
 SG_ Periodic_Displacement_Factor m7 : 8|32@1- (1,0) [-3.4E+038|3.4E+038] "" Vector__XXX
 SG_ Periodic_Current_THD m6 : 8|32@1- (1,0) [-3.4E+038|3.4E+038] "" Vector__XXX
 SG_ Periodic_Current_DC m5 : 8|32@1- (1,0) [-3.4E+038|3.4E+038] "A" Vector__XXX
 SG_ Periodic_Current_ACDC m3 : 8|32@1- (1,0) [-3.4E+038|3.4E+038] "A" Vector__XXX
 SG_ Periodic_Crest_Factor m2 : 8|32@1- (1,0) [-3.4E+038|3.4E+038] "" Vector__XXX
 SG_ Periodic_Active_Power m1 : 8|32@1- (1,0) [-3.4E+038|3.4E+038] "" Vector__XXX

BO_ 298 Periodic_Measurements_Ander: 5 Vector__XXX
 SG_ Periodic_B_Active_Power m3 : 8|32@1- (1,0) [-3.4E+038|3.4E+038] "" Vector__XXX
 SG_ Periodic_A_Voltage_DC m45 : 8|32@1- (1,0) [-3.4E+038|3.4E+038] "V" Vector__XXX
 SG_ Periodic_A_Voltage_ACDC m47 : 8|32@1- (1,0) [-3.4E+038|3.4E+038] "V" Vector__XXX
 SG_ Periodic_A_Voltage_AC m1 : 8|32@1- (1,0) [-3.4E+038|3.4E+038] "V" Vector__XXX
 SG_ Multiplex_Periodic_Values_2 M : 0|8@1+ (1,0) [0|0] "" Vector__XXX

BO_ 2 Periodic_Measurements_Peak: 5 Vector__XXX
 SG_ Periodic_A_Peak_Current_Recoded m1 : 8|32@1- (1,0) [-3.4E+038|3.4E+038] "" Vector__XXX
 SG_ Periodic_A_Peak_Current m14 : 8|32@1- (1,0) [-3.4E+038|3.4E+038] "A" Vector__XXX
 SG_ Multiplex_Periodic_Values_2 M : 0|8@1+ (1,0) [0|0] "" Vector__XXX

BO_ 5 Periodic_Measurements_Dupla: 8 Vector__XXX
 SG_ Periodic_A_Kilowatt_Hour : 32|32@1- (1,0) [-3.4E+038|3.4E+038] "kWh" Vector__XXX
 SG_ Periodic_A_Active_Power : 0|32@1- (1,0) [-3.4E+038|3.4E+038] "" Vector__XXX

BO_ 299 Periodic_Measurements_Cut: 5 Vector__XXX
 SG_ Periodic_A_Power_Factor_Angle m9 : 8|32@1- (1,0) [-3.4E+038|3.4E+038] "" Vector__XXX
 SG_ Periodic_A_Power_Factor m3 : 8|32@1- (1,0) [-3.4E+038|3.4E+038] "" Vector__XXX
 SG_ Multiplex_Periodic_Values_2 M : 0|8@1+ (1,0) [0|0] "" Vector__XXX

BO_ 4 Periodic_Measurements_Sliced: 5 Vector__XXX
 SG_ Periodic_A_VoltageLL_DC m12 : 8|32@1- (1,0) [-3.4E+038|3.4E+038] "V" Vector__XXX
 SG_ Periodic_A_VoltageLL_ACDC m22 : 8|32@1- (1,0) [-3.4E+038|3.4E+038] "V" Vector__XXX
 SG_ Periodic_A_VoltageLL_AC m35 : 8|32@1- (1,0) [-3.4E+038|3.4E+038] "V" Vector__XXX
 SG_ Periodic_A_Voltage_THD m78 : 8|32@1- (1,0) [-3.4E+038|3.4E+038] "" Vector__XXX
 SG_ Multiplex_Periodic_Values_2 M : 0|8@1+ (1,0) [0|0] "" Vector__XXX

EV_ CAN_Config: 0 [0|16] "" 5 1 DUMMY_NODE_VECTOR3 Vector__XXX;

CM_ BO_ 3221225472 "This is a message for not used signals, created by Vector CANdb++ DBC OLE DB Provider.";
CM_ SG_ 3221225472 Firmware_Version "Firmware Version";
CM_ SG_ 3221225472 Can_Version "Interface Version";
BA_DEF_ EV_  "Nominal_Bit_Rate" INT 5000 1000000;
BA_DEF_ EV_  "Data_Bit_Rate" INT 1000000 10000000;
BA_DEF_ EV_  "Mode" ENUM  "CAN (SJA1000)","CAN","ISO CAN FD","Non-ISO CAN FD";
BA_DEF_ BU_  "ISO11783PDDVersion" ENUM  "0","1","2","3","4";
BA_DEF_ BU_  "ISO11783IOPVersion" ENUM  "0","1","2","3","4";
BA_DEF_ BO_  "SingleFrame" INT 0 1;
BA_DEF_ SG_  "DDI" INT 0 65535;
BA_DEF_ SG_  "SigType" ENUM  "Default","Range","RangeSigned","ASCII","Discrete","Control","ReferencePGN","DTC","StringDelimiter","StringLength","StringLengthControl","MessageCounter","MessageChecksum";
BA_DEF_ SG_  "GenSigILSupport" ENUM  "No","Yes";
BA_DEF_ SG_  "GenSigSendType" ENUM  "Cyclic","OnWrite","OnWriteWithRepetition","OnChange","OnChangeWithRepetition","IfActive","IfActiveWithRepetition","NoSigSendType";
BA_DEF_ SG_  "GenSigInactiveValue" INT 0 0;
BA_DEF_ SG_  "GenSigStartValue" INT 0 2147483647;
BA_DEF_ BO_  "GenMsgILSupport" ENUM  "No","Yes";
BA_DEF_ BU_  "ECU" STRING ;
BA_DEF_ BU_  "NmStationAddress" INT 0 255;
BA_DEF_ BO_  "GenMsgSendType" ENUM  "cyclic","NotUsed","NotUsed","NotUsed","NotUsed","NotUsed","NotUsed","IfActive","noMsgSendType";
BA_DEF_ BO_  "GenMsgRequestable" INT 0 1;
BA_DEF_  "DBName" STRING ;
BA_DEF_  "BusType" STRING ;
BA_DEF_  "ProtocolType" STRING ;
BA_DEF_ BO_  "VFrameFormat" ENUM  "StandardCAN","ExtendedCAN","reserved","J1939PG";
BA_DEF_DEF_  "Nominal_Bit_Rate" 1000000;
BA_DEF_DEF_  "Data_Bit_Rate" 2000000;
BA_DEF_DEF_  "Mode" "CAN (SJA1000)";
BA_DEF_DEF_  "ISO11783PDDVersion" "3";
BA_DEF_DEF_  "ISO11783IOPVersion" "3";
BA_DEF_DEF_  "SingleFrame" 1;
BA_DEF_DEF_  "DDI" 0;
BA_DEF_DEF_  "SigType" "Default";
BA_DEF_DEF_  "GenSigILSupport" "Yes";
BA_DEF_DEF_  "GenSigSendType" "NoSigSendType";
BA_DEF_DEF_  "GenSigInactiveValue" 0;
BA_DEF_DEF_  "GenSigStartValue" 0;
BA_DEF_DEF_  "GenMsgILSupport" "Yes";
BA_DEF_DEF_  "ECU" "";
BA_DEF_DEF_  "NmStationAddress" 254;
BA_DEF_DEF_  "GenMsgSendType" "noMsgSendType";
BA_DEF_DEF_  "GenMsgRequestable" 1;
BA_DEF_DEF_  "DBName" "";
BA_DEF_DEF_  "BusType" "CAN";
BA_DEF_DEF_  "ProtocolType" "ISO11783";
BA_DEF_DEF_  "VFrameFormat" "J1939PG";
BA_ "ProtocolType" "iso11783";
BA_ "DBName" "firstdatabase";
BA_ "ECU" BU_ PPowerSource "FrontPanel";
BA_ "NmStationAddress" BU_ PPowerSource 38;
BA_ "VFrameFormat" BO_ 119 0;
BA_ "VFrameFormat" BO_ 136 0;
BA_ "VFrameFormat" BO_ 3 0;
BA_ "VFrameFormat" BO_ 298 0;
BA_ "VFrameFormat" BO_ 2 0;
BA_ "VFrameFormat" BO_ 5 0;
BA_ "VFrameFormat" BO_ 299 0;
BA_ "VFrameFormat" BO_ 4 0;
BA_ "DDI" SG_ 3221225472 Get_Prot_RMS_Current_Level 8;
BA_ "DDI" SG_ 3221225472 Get_A_Apparent_Power 1;
BA_ "DDI" SG_ 3221225472 Get_A_Current_AC 1;
BA_ "DDI" SG_ 3221225472 Get_VoltageLL_ACDC 1;
BA_ "DDI" SG_ 3221225472 Get_VoltageLL_AC 1;
BA_ "DDI" SG_ 3221225472 Get_VoltageLL_DC 1;
BA_ "DDI" SG_ 3221225472 Get_Voltage_ACDC 1;
BA_ "DDI" SG_ 3221225472 Get_Current_ACDC 1;
BA_ "DDI" SG_ 3221225472 Get_Current_AC 1;
BA_ "DDI" SG_ 3221225472 Get_Current_DC 1;
BA_ "DDI" SG_ 3221225472 Get_Peak_Current 1;
BA_ "DDI" SG_ 3221225472 Get_Peak_Current_Recorded 1;
BA_ "DDI" SG_ 3221225472 Get_Active_Power 1;
BA_ "DDI" SG_ 3221225472 Get_Apparent_Power 1;
BA_ "DDI" SG_ 3221225472 Get_Power_Factor 1;
BA_ "DDI" SG_ 3221225472 Get_Crest_Factor 1;
BA_ "DDI" SG_ 3221225472 Get_Voltage_THD 1;
BA_ "DDI" SG_ 3221225472 Get_Current_THD 1;
BA_ "DDI" SG_ 3221225472 Get_Power_Factor_Angle 1;
BA_ "DDI" SG_ 3221225472 Get_Displacement_Factor 1;
BA_ "DDI" SG_ 3221225472 Get_Distortion_Factor 1;
BA_ "DDI" SG_ 3221225472 Get_Kilowatt_Hour 1;
BA_ "DDI" SG_ 3221225472 Get_KWH_Elapsed_Time 1;
BA_ "DDI" SG_ 3221225472 Get_C_VoltageLL_ACDC 1;
BA_ "DDI" SG_ 3221225472 Get_C_VoltageLL_AC 1;
BA_ "DDI" SG_ 3221225472 Get_C_VoltageLL_DC 1;
BA_ "DDI" SG_ 3221225472 Get_C_Voltage_ACDC 1;
BA_ "DDI" SG_ 3221225472 Get_C_Voltage_DC 1;
BA_ "DDI" SG_ 3221225472 Get_C_Peak_Current_Recorded 1;
BA_ "DDI" SG_ 3221225472 Get_C_Active_Power 1;
BA_ "DDI" SG_ 3221225472 Get_C_Apparent_Power 1;
BA_ "DDI" SG_ 3221225472 Get_C_Crest_Factor 1;
BA_ "DDI" SG_ 3221225472 Get_C_Voltage_THD 1;
BA_ "DDI" SG_ 3221225472 Get_C_Power_Factor_Angle 1;
BA_ "DDI" SG_ 3221225472 Get_C_Distortion_Factor 1;
BA_ "DDI" SG_ 3221225472 Get_C_Kilowatt_Hour 1;
BA_ "DDI" SG_ 3221225472 Get_C_KWH_Elapsed_Time 1;
BA_ "DDI" SG_ 3221225472 Get_B_Frequency 1;
BA_ "DDI" SG_ 3221225472 Get_B_VoltageLL_ACDC 1;
BA_ "DDI" SG_ 3221225472 Get_B_VoltageLL_AC 1;
BA_ "DDI" SG_ 3221225472 Get_B_VoltageLL_DC 1;
BA_ "DDI" SG_ 3221225472 Get_B_Voltage_ACDC 1;
BA_ "DDI" SG_ 3221225472 Get_B_Voltage_DC 1;
BA_ "DDI" SG_ 3221225472 Get_B_Current_ACDC 1;
BA_ "DDI" SG_ 3221225472 Get_B_Current_AC 1;
BA_ "DDI" SG_ 3221225472 Get_B_Current_DC 1;
BA_ "DDI" SG_ 3221225472 Get_B_Peak_Current 1;
BA_ "DDI" SG_ 3221225472 Get_B_Peak_Current_Recorded 1;
BA_ "DDI" SG_ 3221225472 Get_B_Active_Power 1;
BA_ "DDI" SG_ 3221225472 Get_B_Apparent_Power 1;
BA_ "DDI" SG_ 3221225472 Get_B_Power_Factor 1;
BA_ "DDI" SG_ 3221225472 Get_B_Crest_Factor 1;
BA_ "DDI" SG_ 3221225472 Get_B_Voltage_THD 1;
BA_ "DDI" SG_ 3221225472 Get_B_Current_THD 1;
BA_ "DDI" SG_ 3221225472 Get_B_Power_Factor_Angle 1;
BA_ "DDI" SG_ 3221225472 Get_B_Displacement_Factor 1;
BA_ "DDI" SG_ 3221225472 Get_B_Distortion_Factor 1;
BA_ "DDI" SG_ 3221225472 Get_B_Kilowatt_Hour 1;
BA_ "DDI" SG_ 3221225472 Get_B_KWH_Elapsed_Time 1;
BA_ "DDI" SG_ 3221225472 Get_A_VoltageLL_DC 1;
BA_ "DDI" SG_ 3221225472 Get_A_VoltageLL_ACDC 1;
BA_ "DDI" SG_ 3221225472 Get_A_VoltageLL_AC 1;
BA_ "DDI" SG_ 3221225472 Get_A_Voltage_THD 1;
BA_ "DDI" SG_ 3221225472 Get_A_Voltage_ACDC 1;
BA_ "DDI" SG_ 3221225472 Get_A_Power_Factor_Angle 1;
BA_ "DDI" SG_ 3221225472 Get_A_Power_Factor 1;
BA_ "DDI" SG_ 3221225472 Get_A_Peak_Current_Recorded 1;
BA_ "DDI" SG_ 3221225472 Get_A_Peak_Current 1;
BA_ "DDI" SG_ 3221225472 Get_A_KWH_Elapsed_Time 1;
BA_ "DDI" SG_ 3221225472 Get_A_Kilowatt_Hour 1;
BA_ "DDI" SG_ 3221225472 Get_A_Frequency 1;
BA_ "DDI" SG_ 3221225472 Get_A_Distortion_Factor 1;
BA_ "DDI" SG_ 3221225472 Get_A_Displacement_Factor 1;
BA_ "DDI" SG_ 3221225472 Get_A_Current_THD 1;
BA_ "DDI" SG_ 3221225472 Get_A_Current_DC 1;
BA_ "DDI" SG_ 3221225472 Get_A_Current_ACDC 1;
BA_ "DDI" SG_ 3221225472 Get_A_Crest_Factor 1;
BA_ "DDI" SG_ 3221225472 Get_A_Active_Power 1;
BA_ "GenSigStartValue" SG_ 3221225472 Firmware_Version 10;
BA_ "GenSigStartValue" SG_ 3221225472 Can_Version 10;
BA_ "DDI" SG_ 3221225472 SCPI_Response_Next_Page 15;
BA_ "DDI" SG_ 3221225472 SCPI_Char_16_Endianess 15;
BA_ "DDI" SG_ 3221225472 SCPI_COMMAND_LAST_ASWER 15;
BA_ "DDI" SG_ 3221225472 SCPI_WRITE_QUERY 15;
BA_ "DDI" SG_ 3221225472 Protection_Peak_Voltage_Level 7;
BA_ "DDI" SG_ 3221225472 Protection_Peak_Voltage_Margin 7;
BA_ "DDI" SG_ 3221225472 Protection_Peak_Current_Level 7;
BA_ "DDI" SG_ 3221225472 Protection_Peak_Current_Limit 7;
BA_ "DDI" SG_ 3221225472 Protection_Trip_Time 7;
BA_ "DDI" SG_ 3221225472 Protection_RMS_Current_Level 7;
BA_ "DDI" SG_ 3221225472 Set_Enable_KWH 2;
BA_ "DDI" SG_ 3221225472 Set_Reset_KWH 2;
BA_ "DDI" SG_ 3221225472 Periodic_C_KWH_Elapsed_Time 1;
BA_ "DDI" SG_ 3221225472 Periodic_B_KWH_Elapsed_Time 1;
BA_ "DDI" SG_ 3221225472 Periodic_A_KWH_Elapsed_Time 1;
BA_ "DDI" SG_ 3221225472 Periodic_C_Kilowatt_Hour 1;
BA_ "DDI" SG_ 3221225472 Periodic_B_Kilowatt_Hour 1;
BA_ "DDI" SG_ 3221225472 Periodic_C_Distortion_Factor 1;
BA_ "DDI" SG_ 3221225472 Periodic_B_Distortion_Factor 1;
BA_ "DDI" SG_ 3221225472 Periodic_A_Distortion_Factor 1;
BA_ "DDI" SG_ 3221225472 Periodic_C_Displacement_Factor 1;
BA_ "DDI" SG_ 3221225472 Periodic_B_Displacement_Factor 1;
BA_ "DDI" SG_ 3221225472 Periodic_A_Displacement_Factor 1;
BA_ "DDI" SG_ 3221225472 Periodic_C_Power_Factor_Angle 1;
BA_ "DDI" SG_ 3221225472 Periodic_B_Power_Factor_Angle 1;
BA_ "DDI" SG_ 3221225472 Periodic_C_Current_THD 1;
BA_ "DDI" SG_ 3221225472 Periodic_B_Current_THD 1;
BA_ "DDI" SG_ 3221225472 Periodic_C_Voltage_THD 1;
BA_ "DDI" SG_ 3221225472 Periodic_B_Voltage_THD 1;
BA_ "DDI" SG_ 3221225472 Periodic_C_Peak_Current_Recoded 1;
BA_ "DDI" SG_ 3221225472 Periodic_B_Peak_Current_Recoded 1;
BA_ "DDI" SG_ 3221225472 Periodic_C_Crest_Factor 1;
BA_ "DDI" SG_ 3221225472 Periodic_B_Crest_Factor 1;
BA_ "DDI" SG_ 3221225472 Periodic_A_Crest_Factor 1;
BA_ "DDI" SG_ 3221225472 Periodic_C_Power_Factor 1;
BA_ "DDI" SG_ 3221225472 Periodic_B_Power_Factor 1;
BA_ "DDI" SG_ 3221225472 Periodic_C_Peak_Current 1;
BA_ "DDI" SG_ 3221225472 Periodic_B_Peak_Current 1;
BA_ "DDI" SG_ 3221225472 Periodic_C_Active_Power 1;
BA_ "DDI" SG_ 3221225472 Periodic_C_Current_DC 1;
BA_ "DDI" SG_ 3221225472 Periodic_B_Current_DC 1;
BA_ "DDI" SG_ 3221225472 Periodic_C_Current_ACDC 1;
BA_ "DDI" SG_ 3221225472 Periodic_B_Current_ACDC 1;
BA_ "DDI" SG_ 3221225472 Periodic_C_Voltage_DC 1;
BA_ "DDI" SG_ 3221225472 Periodic_B_Voltage_DC 1;
BA_ "DDI" SG_ 3221225472 Periodic_C_Voltage_AC 1;
BA_ "DDI" SG_ 3221225472 Periodic_B_Voltage_AC 1;
BA_ "DDI" SG_ 3221225472 Periodic_C_Voltage_ACDC 1;
BA_ "DDI" SG_ 3221225472 Periodic_B_Voltage_ACDC 1;
BA_ "DDI" SG_ 3221225472 Periodic_C_VoltageLL_DC 1;
BA_ "DDI" SG_ 3221225472 Periodic_B_VoltageLL_DC 1;
BA_ "DDI" SG_ 3221225472 Periodic_C_VoltageLL_AC 1;
BA_ "DDI" SG_ 3221225472 Periodic_B_VoltageLL_AC 1;
BA_ "DDI" SG_ 3221225472 Periodic_C_VoltageLL_ACDC 1;
BA_ "DDI" SG_ 3221225472 Periodic_B_VoltageLL_ACDC 1;
BA_ "DDI" SG_ 3221225472 Periodic_C_Frequency 1;
BA_ "DDI" SG_ 3221225472 Periodic_B_Frequency 1;
BA_ "DDI" SG_ 3221225472 Periodic_A_Frequency 1;
BA_ "DDI" SG_ 3221225472 Get_Set_Phase_Offset_Output_C 4;
BA_ "DDI" SG_ 3221225472 Get_Set_Phase_Offset_Output_B 4;
BA_ "DDI" SG_ 3221225472 Get_Set_KVA_Limit_C 4;
BA_ "DDI" SG_ 3221225472 Get_Set_KVA_Limit_B 4;
BA_ "DDI" SG_ 3221225472 Get_Set_KVA_Limit_A 4;
BA_ "DDI" SG_ 3221225472 Get_Set_Current_Limit_C 4;
BA_ "DDI" SG_ 3221225472 Get_Set_Current_Limit_B 4;
BA_ "DDI" SG_ 3221225472 Get_Set_Power_Limit_C 4;
BA_ "DDI" SG_ 3221225472 Get_Set_Power_Limit_B 4;
BA_ "DDI" SG_ 3221225472 Get_Set_Power_Limit_A 4;
BA_ "DDI" SG_ 3221225472 Get_Set_Program_Voltage_DC_C 4;
BA_ "DDI" SG_ 3221225472 Get_Set_Program_Voltage_DC_B 4;
BA_ "DDI" SG_ 3221225472 Get_Set_Program_Voltage_DC_A 4;
BA_ "DDI" SG_ 3221225472 Get_Set_Program_Voltage_AC_C 4;
BA_ "DDI" SG_ 3221225472 Get_Set_Program_Voltage_AC_B 4;
BA_ "DDI" SG_ 3221225472 Get_Set_Program_Voltage_AC_A 4;
BA_ "DDI" SG_ 3221225472 Get_Set_Program_Voltage_AC 4;
BA_ "DDI" SG_ 3221225472 Get_Set_Program_Frequency_C 4;
BA_ "DDI" SG_ 3221225472 Get_Set_Program_Frequency_B 4;
BA_ "DDI" SG_ 3221225472 Get_Set_Program_Frequency_A 4;
BA_ "DDI" SG_ 3221225472 Get_Prot_Peak_Voltage_Level 8;
BA_ "DDI" SG_ 3221225472 Get_Prot_Peak_Voltage_Margin 8;
BA_ "DDI" SG_ 3221225472 Get_Prot_Peak_Current_Level 8;
BA_ "DDI" SG_ 3221225472 Get_Prot_Peak_Current_Limit 8;
BA_ "DDI" SG_ 3221225472 Get_Prot_Trip_Time 8;
BA_ "DDI" SG_ 3221225472 Protection_Power_Level 7;
BA_ "DDI" SG_ 3221225472 Protection_KVA_Level 7;
BA_ "DDI" SG_ 3221225472 Protection_RMS_Power 7;
BA_ "DDI" SG_ 3221225472 Protection_RMS_Current 7;
BA_ "DDI" SG_ 3221225472 Protection_Peak_Voltage_Mode 7;
BA_ "DDI" SG_ 3221225472 Protection_Peak_Voltage 7;
BA_ "DDI" SG_ 3221225472 Protection_Peak_Current 7;
BA_ "DDI" SG_ 3221225472 Get_Prot_KVA_Level 8;
BA_ "DDI" SG_ 3221225472 Get_Prot_Power_Level 8;
BA_ "DDI" SG_ 3221225472 Get_Prot_RMS_Power 8;
BA_ "DDI" SG_ 3221225472 Get_Prot_RMS_Current 8;
BA_ "DDI" SG_ 3221225472 Get_Prot_Peak_Voltage_Mode 8;
BA_ "DDI" SG_ 3221225472 Get_Prot_Peak_Current 8;
BA_ "DDI" SG_ 3221225472 Get_Prot_Peak_Voltage 8;
BA_ "DDI" SG_ 3221225472 Get_Set_Enable_Output 4;
BA_ "DDI" SG_ 3221225472 Get_Set_Program_Voltage_DC 4;
BA_ "DDI" SG_ 3221225472 Get_Set_Power_Limit 4;
BA_ "DDI" SG_ 3221225472 Get_Set_KVA_Limit 4;
BA_ "DDI" SG_ 3221225472 Get_Set_Current_Limit 4;
BA_ "DDI" SG_ 3221225472 Get_Set_Current_Limit_A 4;
BA_ "DDI" SG_ 3221225472 Get_Set_Program_Frequency 4;
BA_ "DDI" SG_ 3221225472 Get_B_Voltage_AC 1;
BA_ "DDI" SG_ 3221225472 Get_Frequency 1;
BA_ "DDI" SG_ 3221225472 Get_C_Power_Factor 1;
BA_ "DDI" SG_ 3221225472 Get_C_Peak_Current 1;
BA_ "DDI" SG_ 3221225472 Get_C_Frequency 1;
BA_ "DDI" SG_ 3221225472 Get_C_Displacement_Factor 1;
BA_ "DDI" SG_ 3221225472 Get_C_Current_THD 1;
BA_ "DDI" SG_ 3221225472 Get_C_Current_DC 1;
BA_ "DDI" SG_ 3221225472 Get_C_Current_ACDC 1;
BA_ "DDI" SG_ 3221225472 Get_C_Current_AC 1;
BA_ "DDI" SG_ 3221225472 Get_C_Voltage_AC 1;
BA_ "DDI" SG_ 3221225472 Get_A_Voltage_DC 1;
BA_ "DDI" SG_ 3221225472 Get_A_Voltage_AC 1;
BA_ "DDI" SG_ 3221225472 Periodic_A_Current_THD 1;
BA_ "DDI" SG_ 3221225472 Periodic_A_Current_DC 1;
BA_ "DDI" SG_ 3221225472 Periodic_A_Current_ACDC 1;
BA_ "DDI" SG_ 3221225472 Setpoint_Power_Limit_C 3;
BA_ "DDI" SG_ 3221225472 Setpoint_Power_Limit_B 3;
BA_ "DDI" SG_ 3221225472 Setpoint_Power_Limit_A 3;
BA_ "DDI" SG_ 3221225472 Setpoint_Power_Limit 3;
BA_ "DDI" SG_ 3221225472 Setpoint_Phase_Offset_Output_C 3;
BA_ "DDI" SG_ 3221225472 Setpoint_Phase_Offset_Output_B 3;
BA_ "DDI" SG_ 3221225472 Setpoint_KVA_Limit_C 3;
BA_ "DDI" SG_ 3221225472 Setpoint_KVA_Limit_B 3;
BA_ "DDI" SG_ 3221225472 Setpoint_KVA_Limit_A 3;
BA_ "DDI" SG_ 3221225472 Setpoint_KVA_Limit 3;
BA_ "DDI" SG_ 3221225472 Setpoint_Enable_Output 3;
BA_ "DDI" SG_ 3221225472 Setpoint_Current_Limit_C 3;
BA_ "DDI" SG_ 3221225472 Setpoint_Current_Limit_B 3;
BA_ "DDI" SG_ 3221225472 Setpoint_Current_Limit 3;
BA_ "DDI" SG_ 3221225472 Setpoint_Current_Limit_A 3;
BA_ "DDI" SG_ 3221225472 Setpoint_Program_Voltage_DC_C 3;
BA_ "DDI" SG_ 3221225472 Setpoint_Program_Voltage_DC_B 3;
BA_ "DDI" SG_ 3221225472 Setpoint_Program_Voltage_DC_A 3;
BA_ "DDI" SG_ 3221225472 Setpoint_Program_Voltage_DC 3;
BA_ "DDI" SG_ 3221225472 Setpoint_Program_Voltage_AC_C 3;
BA_ "DDI" SG_ 3221225472 Setpoint_Program_Voltage_AC_B 3;
BA_ "DDI" SG_ 3221225472 Setpoint_Program_Voltage_AC_A 3;
BA_ "DDI" SG_ 3221225472 Setpoint_Program_Voltage_AC 3;
BA_ "DDI" SG_ 3221225472 Setpoint_Program_Frequency_C 3;
BA_ "DDI" SG_ 3221225472 Setpoint_Program_Frequency_B 3;
BA_ "DDI" SG_ 3221225472 Setpoint_Program_Frequency_A 3;
BA_ "DDI" SG_ 3221225472 Setpoint_Program_Frequency 3;
BA_ "DDI" SG_ 3221225472 Get_Con_Slew_Voltage_DC 6;
BA_ "DDI" SG_ 3221225472 Get_Con_Slew_Voltage_AC 6;
BA_ "DDI" SG_ 3221225472 Get_Con_Slew_Ramp_Time 6;
BA_ "DDI" SG_ 3221225472 Get_Con_Slew_Phase 6;
BA_ "DDI" SG_ 3221225472 Get_Con_Slew_Frequency 6;
BA_ "DDI" SG_ 3221225472 Config_Slew_Voltage_DC 5;
BA_ "DDI" SG_ 3221225472 Config_Slew_Voltage_AC 5;
BA_ "DDI" SG_ 3221225472 Config_Slew_Ramp_Time 5;
BA_ "DDI" SG_ 3221225472 Config_Slew_Phase 5;
BA_ "DDI" SG_ 3221225472 Config_Slew_Frequency 5;
BA_ "DDI" SG_ 3221225472 Get_Con_Unit_Max_CSC_Gain 6;
BA_ "DDI" SG_ 3221225472 Get_Con_Unit_Out_Phase_Disable 6;
BA_ "DDI" SG_ 3221225472 Get_Con_Unit_Update_Phase 6;
BA_ "DDI" SG_ 3221225472 Config_Unit_Update_Phase 5;
BA_ "DDI" SG_ 3221225472 Config_Unit_Out_Phase_Disable 5;
BA_ "DDI" SG_ 3221225472 Config_Unit_Max_CSC_Gain 5;
BA_ "DDI" SG_ 3221225472 Config_Unit_Voltage_Range 5;
BA_ "DDI" SG_ 3221225472 Config_Unit_Phase_Rotation 5;
BA_ "DDI" SG_ 3221225472 Config_Unit_Out_Impedance_Mode 5;
BA_ "DDI" SG_ 3221225472 Config_Unit_Mode 5;
BA_ "DDI" SG_ 3221225472 Config_Unit_Form 5;
BA_ "GenSigStartValue" SG_ 3221225472 Config_Unit_Form 1;
BA_ "DDI" SG_ 3221225472 Config_Unit_Fault_On_Saturation 5;
BA_ "DDI" SG_ 3221225472 Config_Unit_C_Self_Calibration 5;
BA_ "DDI" SG_ 119 Get_Voltage_DC 1;
BA_ "DDI" SG_ 119 Get_Voltage_AC 1;
BA_ "DDI" SG_ 136 Get_Con_Unit_Voltage_Range 6;
BA_ "DDI" SG_ 136 Get_Con_Unit_Phase_Rotation 6;
BA_ "DDI" SG_ 136 Get_Con_Unit_Out_Impedance_Mode 6;
BA_ "DDI" SG_ 136 Get_Con_Unit_Mode 6;
BA_ "DDI" SG_ 136 Get_Con_Unit_Form 6;
BA_ "GenSigStartValue" SG_ 136 Get_Con_Unit_Form 1;
BA_ "DDI" SG_ 136 Get_Con_Unit_Fault_On_Saturation 6;
BA_ "DDI" SG_ 136 Get_Con_Unit_C_Self_Calibration 6;
BA_ "DDI" SG_ 3 Periodic_VoltageLL_DC 1;
BA_ "DDI" SG_ 3 Periodic_VoltageLL_ACDC 1;
BA_ "DDI" SG_ 3 Periodic_VoltageLL_AC 1;
BA_ "DDI" SG_ 3 Periodic_Voltage_THD 1;
BA_ "DDI" SG_ 3 Periodic_Voltage_DC 1;
BA_ "DDI" SG_ 3 Periodic_Voltage_ACDC 1;
BA_ "DDI" SG_ 3 Periodic_Voltage_AC 1;
BA_ "DDI" SG_ 3 Periodic_Power_Factor_Angle 1;
BA_ "DDI" SG_ 3 Periodic_Power_Factor 1;
BA_ "DDI" SG_ 3 Periodic_Peak_Current_Recoded 1;
BA_ "DDI" SG_ 3 Periodic_Peak_Current 1;
BA_ "DDI" SG_ 3 Periodic_KWH_Elapsed_Time 1;
BA_ "DDI" SG_ 3 Periodic_Kilowatt_Hour 1;
BA_ "DDI" SG_ 3 Periodic_Frequency 1;
BA_ "DDI" SG_ 3 Periodic_Distortion_Factor 1;
BA_ "DDI" SG_ 3 Periodic_Displacement_Factor 1;
BA_ "DDI" SG_ 3 Periodic_Current_THD 1;
BA_ "DDI" SG_ 3 Periodic_Current_DC 1;
BA_ "DDI" SG_ 3 Periodic_Current_ACDC 1;
BA_ "DDI" SG_ 3 Periodic_Crest_Factor 1;
BA_ "DDI" SG_ 3 Periodic_Active_Power 1;
BA_ "DDI" SG_ 298 Periodic_B_Active_Power 1;
BA_ "DDI" SG_ 298 Periodic_A_Voltage_DC 1;
BA_ "DDI" SG_ 298 Periodic_A_Voltage_ACDC 1;
BA_ "DDI" SG_ 298 Periodic_A_Voltage_AC 1;
BA_ "DDI" SG_ 2 Periodic_A_Peak_Current_Recoded 1;
BA_ "DDI" SG_ 2 Periodic_A_Peak_Current 1;
BA_ "DDI" SG_ 5 Periodic_A_Kilowatt_Hour 1;
BA_ "DDI" SG_ 5 Periodic_A_Active_Power 1;
BA_ "DDI" SG_ 299 Periodic_A_Power_Factor_Angle 1;
BA_ "DDI" SG_ 299 Periodic_A_Power_Factor 1;
BA_ "DDI" SG_ 4 Periodic_A_VoltageLL_DC 1;
BA_ "DDI" SG_ 4 Periodic_A_VoltageLL_ACDC 1;
BA_ "DDI" SG_ 4 Periodic_A_VoltageLL_AC 1;
BA_ "DDI" SG_ 4 Periodic_A_Voltage_THD 1;
BA_ "Nominal_Bit_Rate" EV_ CAN_Config 500000;
BA_ "Mode" EV_ CAN_Config 1;
SIG_VALTYPE_ 3221225472 Get_Prot_RMS_Current_Level : 1;
SIG_VALTYPE_ 3221225472 Get_A_Apparent_Power : 1;
SIG_VALTYPE_ 3221225472 Get_A_Current_AC : 1;
SIG_VALTYPE_ 3221225472 Get_A_VoltageLL_DC : 1;
SIG_VALTYPE_ 3221225472 Get_A_VoltageLL_ACDC : 1;
SIG_VALTYPE_ 3221225472 Get_A_VoltageLL_AC : 1;
SIG_VALTYPE_ 3221225472 Get_A_Voltage_THD : 1;
SIG_VALTYPE_ 3221225472 Get_A_Voltage_ACDC : 1;
SIG_VALTYPE_ 3221225472 Get_A_Power_Factor_Angle : 1;
SIG_VALTYPE_ 3221225472 Get_A_Power_Factor : 1;
SIG_VALTYPE_ 3221225472 Get_A_Peak_Current_Recorded : 1;
SIG_VALTYPE_ 3221225472 Get_A_Peak_Current : 1;
SIG_VALTYPE_ 3221225472 Get_A_KWH_Elapsed_Time : 1;
SIG_VALTYPE_ 3221225472 Get_A_Kilowatt_Hour : 1;
SIG_VALTYPE_ 3221225472 Get_A_Frequency : 1;
SIG_VALTYPE_ 3221225472 Get_A_Distortion_Factor : 1;
SIG_VALTYPE_ 3221225472 Get_A_Displacement_Factor : 1;
SIG_VALTYPE_ 3221225472 Get_A_Current_THD : 1;
SIG_VALTYPE_ 3221225472 Get_A_Current_DC : 1;
SIG_VALTYPE_ 3221225472 Get_A_Current_ACDC : 1;
SIG_VALTYPE_ 3221225472 Get_A_Crest_Factor : 1;
SIG_VALTYPE_ 3221225472 Get_A_Active_Power : 1;
SIG_VALTYPE_ 3221225472 Protection_Peak_Voltage_Level : 1;
SIG_VALTYPE_ 3221225472 Protection_Peak_Voltage_Margin : 1;
SIG_VALTYPE_ 3221225472 Protection_Peak_Current_Level : 1;
SIG_VALTYPE_ 3221225472 Protection_Peak_Current_Limit : 1;
SIG_VALTYPE_ 3221225472 Protection_Trip_Time : 1;
SIG_VALTYPE_ 3221225472 Protection_RMS_Current_Level : 1;
SIG_VALTYPE_ 3221225472 Periodic_C_KWH_Elapsed_Time : 1;
SIG_VALTYPE_ 3221225472 Periodic_B_KWH_Elapsed_Time : 1;
SIG_VALTYPE_ 3221225472 Periodic_A_KWH_Elapsed_Time : 1;
SIG_VALTYPE_ 3221225472 Periodic_C_Kilowatt_Hour : 1;
SIG_VALTYPE_ 3221225472 Periodic_B_Kilowatt_Hour : 1;
SIG_VALTYPE_ 3221225472 Periodic_C_Distortion_Factor : 1;
SIG_VALTYPE_ 3221225472 Periodic_B_Distortion_Factor : 1;
SIG_VALTYPE_ 3221225472 Periodic_A_Distortion_Factor : 1;
SIG_VALTYPE_ 3221225472 Periodic_C_Displacement_Factor : 1;
SIG_VALTYPE_ 3221225472 Periodic_B_Displacement_Factor : 1;
SIG_VALTYPE_ 3221225472 Periodic_A_Displacement_Factor : 1;
SIG_VALTYPE_ 3221225472 Periodic_C_Power_Factor_Angle : 1;
SIG_VALTYPE_ 3221225472 Periodic_B_Power_Factor_Angle : 1;
SIG_VALTYPE_ 3221225472 Periodic_C_Current_THD : 1;
SIG_VALTYPE_ 3221225472 Periodic_B_Current_THD : 1;
SIG_VALTYPE_ 3221225472 Periodic_C_Voltage_THD : 1;
SIG_VALTYPE_ 3221225472 Periodic_B_Voltage_THD : 1;
SIG_VALTYPE_ 3221225472 Periodic_C_Peak_Current_Recoded : 1;
SIG_VALTYPE_ 3221225472 Periodic_B_Peak_Current_Recoded : 1;
SIG_VALTYPE_ 3221225472 Periodic_C_Crest_Factor : 1;
SIG_VALTYPE_ 3221225472 Periodic_B_Crest_Factor : 1;
SIG_VALTYPE_ 3221225472 Periodic_A_Crest_Factor : 1;
SIG_VALTYPE_ 3221225472 Periodic_C_Power_Factor : 1;
SIG_VALTYPE_ 3221225472 Periodic_B_Power_Factor : 1;
SIG_VALTYPE_ 3221225472 Periodic_C_Peak_Current : 1;
SIG_VALTYPE_ 3221225472 Periodic_B_Peak_Current : 1;
SIG_VALTYPE_ 3221225472 Periodic_C_Active_Power : 1;
SIG_VALTYPE_ 3221225472 Periodic_C_Current_DC : 1;
SIG_VALTYPE_ 3221225472 Periodic_B_Current_DC : 1;
SIG_VALTYPE_ 3221225472 Periodic_C_Current_ACDC : 1;
SIG_VALTYPE_ 3221225472 Periodic_B_Current_ACDC : 1;
SIG_VALTYPE_ 3221225472 Periodic_C_Voltage_DC : 1;
SIG_VALTYPE_ 3221225472 Periodic_B_Voltage_DC : 1;
SIG_VALTYPE_ 3221225472 Periodic_C_Voltage_AC : 1;
SIG_VALTYPE_ 3221225472 Periodic_B_Voltage_AC : 1;
SIG_VALTYPE_ 3221225472 Periodic_C_Voltage_ACDC : 1;
SIG_VALTYPE_ 3221225472 Periodic_B_Voltage_ACDC : 1;
SIG_VALTYPE_ 3221225472 Periodic_C_VoltageLL_DC : 1;
SIG_VALTYPE_ 3221225472 Periodic_B_VoltageLL_DC : 1;
SIG_VALTYPE_ 3221225472 Periodic_C_VoltageLL_AC : 1;
SIG_VALTYPE_ 3221225472 Periodic_B_VoltageLL_AC : 1;
SIG_VALTYPE_ 3221225472 Periodic_C_VoltageLL_ACDC : 1;
SIG_VALTYPE_ 3221225472 Periodic_B_VoltageLL_ACDC : 1;
SIG_VALTYPE_ 3221225472 Periodic_C_Frequency : 1;
SIG_VALTYPE_ 3221225472 Periodic_B_Frequency : 1;
SIG_VALTYPE_ 3221225472 Periodic_A_Frequency : 1;
SIG_VALTYPE_ 3221225472 Get_Set_Phase_Offset_Output_C : 1;
SIG_VALTYPE_ 3221225472 Get_Set_Phase_Offset_Output_B : 1;
SIG_VALTYPE_ 3221225472 Get_Set_KVA_Limit_C : 1;
SIG_VALTYPE_ 3221225472 Get_Set_KVA_Limit_B : 1;
SIG_VALTYPE_ 3221225472 Get_Set_KVA_Limit_A : 1;
SIG_VALTYPE_ 3221225472 Get_Set_Current_Limit_C : 1;
SIG_VALTYPE_ 3221225472 Get_Set_Current_Limit_B : 1;
SIG_VALTYPE_ 3221225472 Get_Set_Power_Limit_C : 1;
SIG_VALTYPE_ 3221225472 Get_Set_Power_Limit_B : 1;
SIG_VALTYPE_ 3221225472 Get_Set_Power_Limit_A : 1;
SIG_VALTYPE_ 3221225472 Get_Set_Program_Voltage_DC_C : 1;
SIG_VALTYPE_ 3221225472 Get_Set_Program_Voltage_DC_B : 1;
SIG_VALTYPE_ 3221225472 Get_Set_Program_Voltage_DC_A : 1;
SIG_VALTYPE_ 3221225472 Get_Set_Program_Voltage_AC_C : 1;
SIG_VALTYPE_ 3221225472 Get_Set_Program_Voltage_AC_B : 1;
SIG_VALTYPE_ 3221225472 Get_Set_Program_Voltage_AC_A : 1;
SIG_VALTYPE_ 3221225472 Get_Set_Program_Voltage_AC : 1;
SIG_VALTYPE_ 3221225472 Get_Set_Program_Frequency_C : 1;
SIG_VALTYPE_ 3221225472 Get_Set_Program_Frequency_B : 1;
SIG_VALTYPE_ 3221225472 Get_Set_Program_Frequency_A : 1;
SIG_VALTYPE_ 3221225472 Protection_Power_Level : 1;
SIG_VALTYPE_ 3221225472 Protection_KVA_Level : 1;
SIG_VALTYPE_ 3221225472 Get_Set_Program_Voltage_DC : 1;
SIG_VALTYPE_ 3221225472 Get_Set_Power_Limit : 1;
SIG_VALTYPE_ 3221225472 Get_Set_KVA_Limit : 1;
SIG_VALTYPE_ 3221225472 Get_Set_Current_Limit : 1;
SIG_VALTYPE_ 3221225472 Get_Set_Current_Limit_A : 1;
SIG_VALTYPE_ 3221225472 Get_Set_Program_Frequency : 1;
SIG_VALTYPE_ 3221225472 Get_A_Voltage_DC : 1;
SIG_VALTYPE_ 3221225472 Get_A_Voltage_AC : 1;
SIG_VALTYPE_ 3221225472 Periodic_A_Current_THD : 1;
SIG_VALTYPE_ 3221225472 Periodic_A_Current_DC : 1;
SIG_VALTYPE_ 3221225472 Periodic_A_Current_ACDC : 1;
SIG_VALTYPE_ 3221225472 Setpoint_Power_Limit_C : 1;
SIG_VALTYPE_ 3221225472 Setpoint_Power_Limit_B : 1;
SIG_VALTYPE_ 3221225472 Setpoint_Power_Limit_A : 1;
SIG_VALTYPE_ 3221225472 Setpoint_Power_Limit : 1;
SIG_VALTYPE_ 3221225472 Setpoint_Phase_Offset_Output_C : 1;
SIG_VALTYPE_ 3221225472 Setpoint_Phase_Offset_Output_B : 1;
SIG_VALTYPE_ 3221225472 Setpoint_KVA_Limit_C : 1;
SIG_VALTYPE_ 3221225472 Setpoint_KVA_Limit_B : 1;
SIG_VALTYPE_ 3221225472 Setpoint_KVA_Limit_A : 1;
SIG_VALTYPE_ 3221225472 Setpoint_KVA_Limit : 1;
SIG_VALTYPE_ 3221225472 Setpoint_Current_Limit_C : 1;
SIG_VALTYPE_ 3221225472 Setpoint_Current_Limit_B : 1;
SIG_VALTYPE_ 3221225472 Setpoint_Current_Limit : 1;
SIG_VALTYPE_ 3221225472 Setpoint_Current_Limit_A : 1;
SIG_VALTYPE_ 3221225472 Setpoint_Program_Voltage_DC_C : 1;
SIG_VALTYPE_ 3221225472 Setpoint_Program_Voltage_DC_B : 1;
SIG_VALTYPE_ 3221225472 Setpoint_Program_Voltage_DC_A : 1;
SIG_VALTYPE_ 3221225472 Setpoint_Program_Voltage_DC : 1;
SIG_VALTYPE_ 3221225472 Setpoint_Program_Voltage_AC_C : 1;
SIG_VALTYPE_ 3221225472 Setpoint_Program_Voltage_AC_B : 1;
SIG_VALTYPE_ 3221225472 Setpoint_Program_Voltage_AC_A : 1;
SIG_VALTYPE_ 3221225472 Setpoint_Program_Voltage_AC : 1;
SIG_VALTYPE_ 3221225472 Setpoint_Program_Frequency_C : 1;
SIG_VALTYPE_ 3221225472 Setpoint_Program_Frequency_B : 1;
SIG_VALTYPE_ 3221225472 Setpoint_Program_Frequency_A : 1;
SIG_VALTYPE_ 3221225472 Setpoint_Program_Frequency : 1;
SIG_VALTYPE_ 3221225472 Get_Con_Slew_Voltage_DC : 1;
SIG_VALTYPE_ 3221225472 Get_Con_Slew_Voltage_AC : 1;
SIG_VALTYPE_ 3221225472 Get_Con_Slew_Ramp_Time : 1;
SIG_VALTYPE_ 3221225472 Get_Con_Slew_Phase : 1;
SIG_VALTYPE_ 3221225472 Get_Con_Slew_Frequency : 1;
SIG_VALTYPE_ 3221225472 Config_Slew_Voltage_DC : 1;
SIG_VALTYPE_ 3221225472 Config_Slew_Voltage_AC : 1;
SIG_VALTYPE_ 3221225472 Config_Slew_Ramp_Time : 1;
SIG_VALTYPE_ 3221225472 Config_Slew_Phase : 1;
SIG_VALTYPE_ 3221225472 Config_Slew_Frequency : 1;
SIG_VALTYPE_ 3221225472 Get_Con_Unit_Max_CSC_Gain : 1;
SIG_VALTYPE_ 3221225472 Get_Con_Unit_Out_Phase_Disable : 1;
SIG_VALTYPE_ 3221225472 Get_Con_Unit_Update_Phase : 1;
SIG_VALTYPE_ 3221225472 Config_Unit_Update_Phase : 1;
SIG_VALTYPE_ 3221225472 Config_Unit_Out_Phase_Disable : 1;
SIG_VALTYPE_ 3221225472 Config_Unit_Max_CSC_Gain : 1;
SIG_VALTYPE_ 3 Periodic_VoltageLL_DC : 1;
SIG_VALTYPE_ 3 Periodic_VoltageLL_ACDC : 1;
SIG_VALTYPE_ 3 Periodic_VoltageLL_AC : 1;
SIG_VALTYPE_ 3 Periodic_Voltage_THD : 1;
SIG_VALTYPE_ 3 Periodic_Voltage_DC : 1;
SIG_VALTYPE_ 3 Periodic_Voltage_ACDC : 1;
SIG_VALTYPE_ 3 Periodic_Voltage_AC : 1;
SIG_VALTYPE_ 3 Periodic_Power_Factor_Angle : 1;
SIG_VALTYPE_ 3 Periodic_Power_Factor : 1;
SIG_VALTYPE_ 3 Periodic_Peak_Current_Recoded : 1;
SIG_VALTYPE_ 3 Periodic_Peak_Current : 1;
SIG_VALTYPE_ 3 Periodic_KWH_Elapsed_Time : 1;
SIG_VALTYPE_ 3 Periodic_Kilowatt_Hour : 1;
SIG_VALTYPE_ 3 Periodic_Frequency : 1;
SIG_VALTYPE_ 3 Periodic_Distortion_Factor : 1;
SIG_VALTYPE_ 3 Periodic_Displacement_Factor : 1;
SIG_VALTYPE_ 3 Periodic_Current_THD : 1;
SIG_VALTYPE_ 3 Periodic_Current_DC : 1;
SIG_VALTYPE_ 3 Periodic_Current_ACDC : 1;
SIG_VALTYPE_ 3 Periodic_Crest_Factor : 1;
SIG_VALTYPE_ 3 Periodic_Active_Power : 1;
SIG_VALTYPE_ 298 Periodic_B_Active_Power : 1;
SIG_VALTYPE_ 298 Periodic_A_Voltage_DC : 1;
SIG_VALTYPE_ 298 Periodic_A_Voltage_ACDC : 1;
SIG_VALTYPE_ 298 Periodic_A_Voltage_AC : 1;
SIG_VALTYPE_ 2 Periodic_A_Peak_Current_Recoded : 1;
SIG_VALTYPE_ 2 Periodic_A_Peak_Current : 1;
SIG_VALTYPE_ 5 Periodic_A_Kilowatt_Hour : 1;
SIG_VALTYPE_ 5 Periodic_A_Active_Power : 1;
SIG_VALTYPE_ 299 Periodic_A_Power_Factor_Angle : 1;
SIG_VALTYPE_ 299 Periodic_A_Power_Factor : 1;
SIG_VALTYPE_ 4 Periodic_A_VoltageLL_DC : 1;
SIG_VALTYPE_ 4 Periodic_A_VoltageLL_ACDC : 1;
SIG_VALTYPE_ 4 Periodic_A_VoltageLL_AC : 1;
SIG_VALTYPE_ 4 Periodic_A_Voltage_THD : 1;
